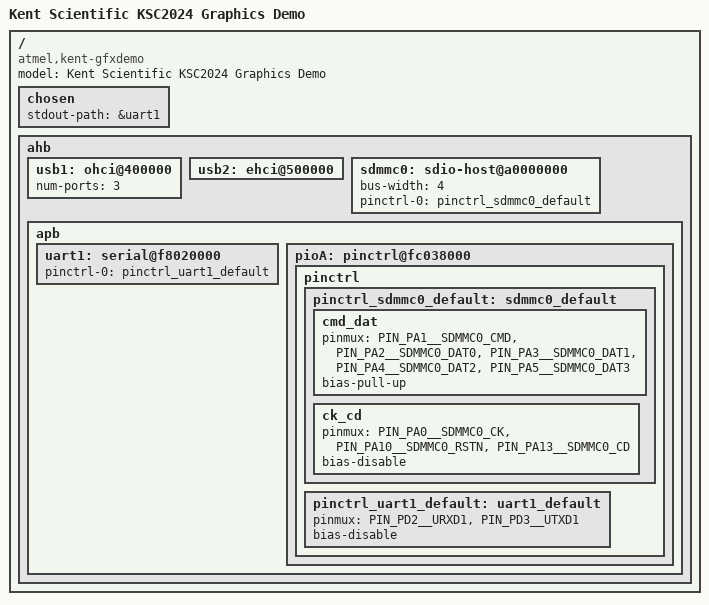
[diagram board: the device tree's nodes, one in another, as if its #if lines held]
// SPDX-License-Identifier: GPL-2.0-or-later OR MIT
/*
 * kent_gfxdemo.dts - Device Tree file for Kent Scientific KSC2024 Graphics Demo
 *
 *  Copyright (C) 2017 Microchip Corporation
 *                     Wenyou Yang <wenyou.yang@microchip.com>
 *  Copyright (C) 2023 Kent Scientific Corporation
 *                     Sam Birch <sam@profirmserv.com>
 *
 * This file is dual-licensed: you can use it either under the terms
 * of the GPL or the X11 license, at your option. Note that this dual
 * licensing only applies to this file, and not this project as a
 * whole.
 *
 *  a) This file is free software; you can redistribute it and/or
 *     modify it under the terms of the GNU General Public License as
 *     published by the Free Software Foundation; either version 2 of the
 *     License, or (at your option) any later version.
 *
 *     This file is distributed in the hope that it will be useful,
 *     but WITHOUT ANY WARRANTY; without even the implied warranty of
 *     MERCHANTABILITY or FITNESS FOR A PARTICULAR PURPOSE.  See the
 *     GNU General Public License for more details.
 *
 * Or, alternatively,
 *
 *  b) Permission is hereby granted, free of charge, to any person
 *     obtaining a copy of this software and associated documentation
 *     files (the "Software"), to deal in the Software without
 *     restriction, including without limitation the rights to use,
 *     copy, modify, merge, publish, distribute, sublicense, and/or
 *     sell copies of the Software, and to permit persons to whom the
 *     Software is furnished to do so, subject to the following
 *     conditions:
 *
 *     The above copyright notice and this permission notice shall be
 *     included in all copies or substantial portions of the Software.
 *
 *     THE SOFTWARE IS PROVIDED "AS IS", WITHOUT WARRANTY OF ANY KIND,
 *     EXPRESS OR IMPLIED, INCLUDING BUT NOT LIMITED TO THE WARRANTIES
 *     OF MERCHANTABILITY, FITNESS FOR A PARTICULAR PURPOSE AND
 *     NONINFRINGEMENT. IN NO EVENT SHALL THE AUTHORS OR COPYRIGHT
 *     HOLDERS BE LIABLE FOR ANY CLAIM, DAMAGES OR OTHER LIABILITY,
 *     WHETHER IN AN ACTION OF CONTRACT, TORT OR OTHERWISE, ARISING
 *     FROM, OUT OF OR IN CONNECTION WITH THE SOFTWARE OR THE USE OR
 *     OTHER DEALINGS IN THE SOFTWARE.
 */
/dts-v1/;
#include <dt-bindings/gpio/gpio.h>
#include "sama5d27_som1.dtsi"
#ifdef CONFIG_CLK_SCMI
#include "sama5d2-optee.dtsi"
#endif

/ {
	model = "Kent Scientific KSC2024 Graphics Demo";
	compatible = "atmel,kent-gfxdemo", "atmel,sama5d2", "atmel,sama5";

	chosen {
		bootph-all;
		stdout-path = &uart1;
	};

	ahb {
		usb1: ohci@400000 {
			num-ports = <3>;
			status = "okay";
		};

		usb2: ehci@500000 {
			status = "okay";
		};

		sdmmc0: sdio-host@a0000000 {
			bus-width = <4>;
			pinctrl-names = "default";
			pinctrl-0 = <&pinctrl_sdmmc0_default>;
			status = "okay";
			bootph-all;
		};

		apb {
			uart1: serial@f8020000 {
				pinctrl-names = "default";
				pinctrl-0 = <&pinctrl_uart1_default>;
				status = "okay";
				bootph-all;
			};

			pioA: pinctrl@fc038000 {
				pinctrl {
					pinctrl_sdmmc0_default: sdmmc0_default {
						cmd_dat {
							pinmux = <PIN_PA1__SDMMC0_CMD>,
								 <PIN_PA2__SDMMC0_DAT0>,
								 <PIN_PA3__SDMMC0_DAT1>,
								 <PIN_PA4__SDMMC0_DAT2>,
								 <PIN_PA5__SDMMC0_DAT3>;
							bias-pull-up;
							bootph-all;
						};

						ck_cd {
							pinmux = <PIN_PA0__SDMMC0_CK>,
								 <PIN_PA10__SDMMC0_RSTN>,
								 <PIN_PA13__SDMMC0_CD>;
							bias-disable;
							bootph-all;
						};
					};

					pinctrl_uart1_default: uart1_default {
						pinmux = <PIN_PD2__URXD1>,
							 <PIN_PD3__UTXD1>;
						bias-disable;
						bootph-all;
					};
				};
			};
		};
	};
};
